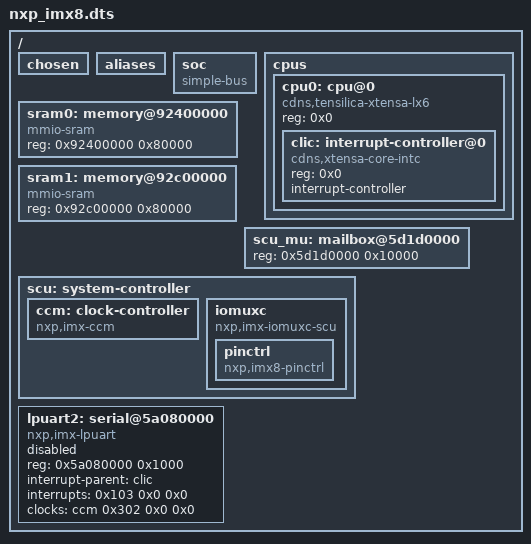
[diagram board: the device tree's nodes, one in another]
/dts-v1/;

/ {
	#address-cells = < 0x1 >;
	#size-cells = < 0x1 >;
	chosen {
	};
	aliases {
	};
	soc {
		#address-cells = < 0x1 >;
		#size-cells = < 0x1 >;
		compatible = "simple-bus";
		ranges;
	};
	cpus {
		#address-cells = < 0x1 >;
		#size-cells = < 0x0 >;
		cpu0: cpu@0 {
			device_type = "cpu";
			compatible = "cdns,tensilica-xtensa-lx6";
			reg = < 0x0 >;
			#address-cells = < 0x1 >;
			#size-cells = < 0x0 >;
			clic: interrupt-controller@0 {
				compatible = "cdns,xtensa-core-intc";
				reg = < 0x0 >;
				interrupt-controller;
				#interrupt-cells = < 0x3 >;
				phandle = < 0x1 >;
			};
		};
	};
	sram0: memory@92400000 {
		device_type = "memory";
		compatible = "mmio-sram";
		reg = < 0x92400000 0x80000 >;
	};
	sram1: memory@92c00000 {
		device_type = "memory";
		compatible = "mmio-sram";
		reg = < 0x92c00000 0x80000 >;
	};
	scu_mu: mailbox@5d1d0000 {
		reg = < 0x5d1d0000 0x10000 >;
	};
	scu: system-controller {
		ccm: clock-controller {
			compatible = "nxp,imx-ccm";
			#clock-cells = < 0x3 >;
			phandle = < 0x2 >;
		};
		iomuxc: iomuxc {
			compatible = "nxp,imx-iomuxc-scu";
			pinctrl: pinctrl {
				compatible = "nxp,imx8-pinctrl";
			};
		};
	};
	lpuart2: serial@5a080000 {
		compatible = "nxp,imx-lpuart", "nxp,kinetis-lpuart";
		reg = < 0x5a080000 0x1000 >;
		interrupt-parent = < &clic >;
		interrupts = < 0x103 0x0 0x0 >;
		clocks = < &ccm 0x302 0x0 0x0 >;
		status = "disabled";
	};
};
